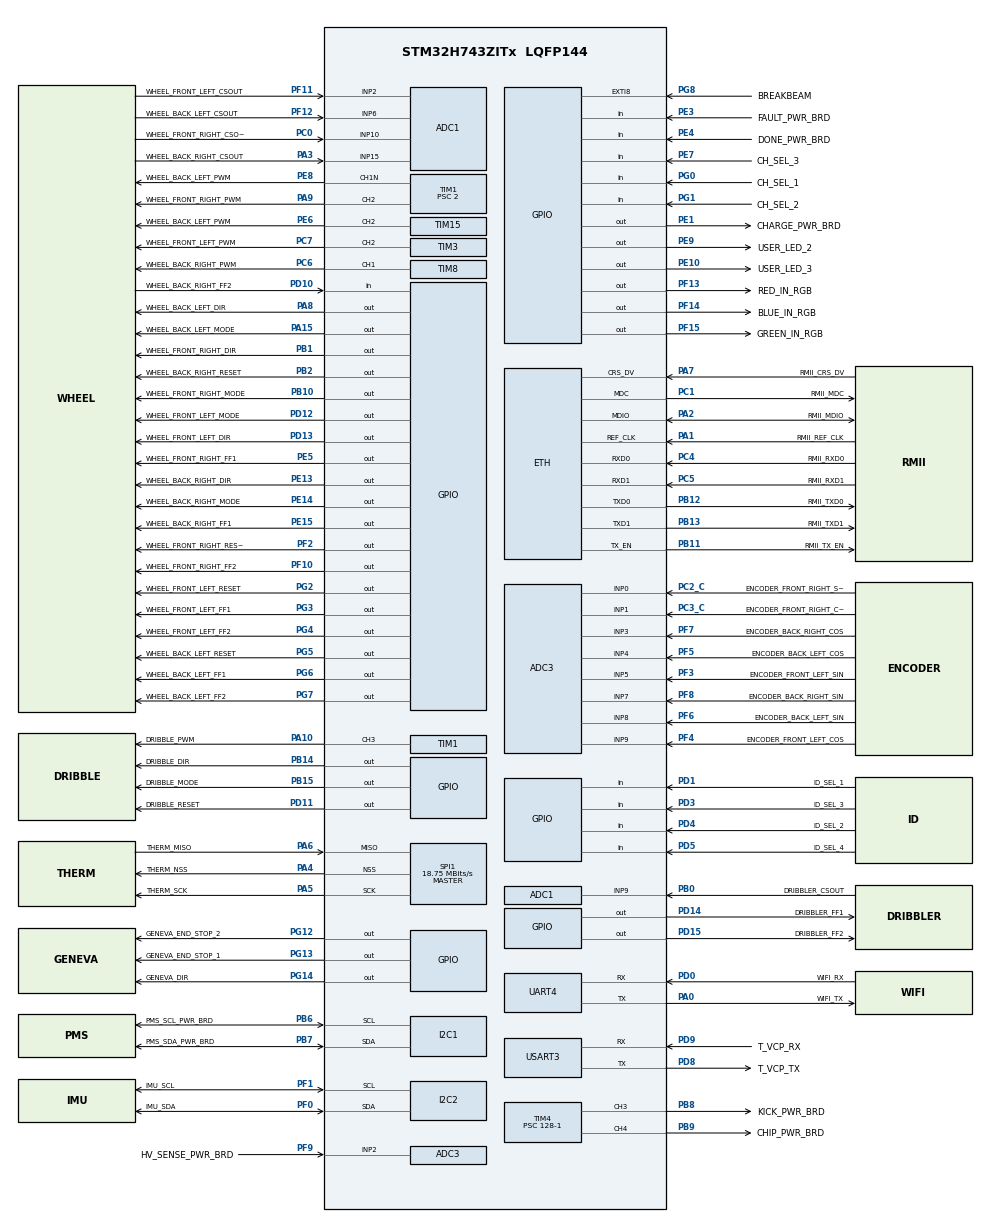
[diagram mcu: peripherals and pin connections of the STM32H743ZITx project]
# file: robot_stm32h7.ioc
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ADC1.Channel-1\#ChannelRegularConversion=ADC_CHANNEL_2
ADC1.ClockPrescaler=ADC_CLOCK_ASYNC_DIV6
ADC1.NbrOfConversionFlag=1
ADC1.OffsetNumber-1\#ChannelRegularConversion=ADC_OFFSET_NONE
ADC1.Rank-1\#ChannelRegularConversion=1
ADC1.SamplingTime-1\#ChannelRegularConversion=ADC_SAMPLETIME_1CYCLE_5
ADC1.master=1
ADC2.Channel-0\#ChannelRegularConversion=ADC_CHANNEL_10
ADC2.ClockPrescaler=ADC_CLOCK_ASYNC_DIV6
ADC2.NbrOfConversionFlag=1
ADC2.OffsetNumber-0\#ChannelRegularConversion=ADC_OFFSET_NONE
ADC2.Rank-0\#ChannelRegularConversion=1
ADC2.SamplingTime-0\#ChannelRegularConversion=ADC_SAMPLETIME_1CYCLE_5
ADC3.Channel-3\#ChannelRegularConversion=ADC_CHANNEL_1
ADC3.ClockPrescaler=ADC_CLOCK_ASYNC_DIV6
ADC3.NbrOfConversionFlag=1
ADC3.OffsetNumber-3\#ChannelRegularConversion=ADC_OFFSET_NONE
ADC3.Rank-3\#ChannelRegularConversion=1
ADC3.SamplingTime-3\#ChannelRegularConversion=ADC_SAMPLETIME_1CYCLE_5
CORTEX_M7.AccessPermission-Cortex_Memory_Protection_Unit_Region0_Settings=MPU_REGION_FULL_ACCESS
CORTEX_M7.AccessPermission-Cortex_Memory_Protection_Unit_Region1_Settings=MPU_REGION_FULL_ACCESS
CORTEX_M7.BaseAddress-Cortex_Memory_Protection_Unit_Region0_Settings=0x30000000
CORTEX_M7.BaseAddress-Cortex_Memory_Protection_Unit_Region1_Settings=0x30024000
CORTEX_M7.CPU_DCache=Enabled
CORTEX_M7.CPU_ICache=Enabled
CORTEX_M7.DisableExec-Cortex_Memory_Protection_Unit_Region0_Settings=MPU_INSTRUCTION_ACCESS_DISABLE
CORTEX_M7.DisableExec-Cortex_Memory_Protection_Unit_Region1_Settings=MPU_INSTRUCTION_ACCESS_DISABLE
CORTEX_M7.Enable-Cortex_Memory_Protection_Unit_Region0_Settings=MPU_REGION_ENABLE
CORTEX_M7.Enable-Cortex_Memory_Protection_Unit_Region1_Settings=MPU_REGION_ENABLE
CORTEX_M7.Enable-Cortex_Memory_Protection_Unit_Region2_Settings=__NULL
CORTEX_M7.IsBufferable-Cortex_Memory_Protection_Unit_Region0_Settings=MPU_ACCESS_NOT_BUFFERABLE
CORTEX_M7.IsBufferable-Cortex_Memory_Protection_Unit_Region1_Settings=MPU_ACCESS_BUFFERABLE
CORTEX_M7.IsCacheable-Cortex_Memory_Protection_Unit_Region1_Settings=MPU_ACCESS_NOT_CACHEABLE
CORTEX_M7.IsShareable-Cortex_Memory_Protection_Unit_Region1_Settings=MPU_ACCESS_NOT_SHAREABLE
CORTEX_M7.MPU_Control=MPU_PRIVILEGED_DEFAULT
CORTEX_M7.Size-Cortex_Memory_Protection_Unit_Region0_Settings=MPU_REGION_SIZE_128KB
CORTEX_M7.Size-Cortex_Memory_Protection_Unit_Region1_Settings=MPU_REGION_SIZE_1KB
CORTEX_M7.TypeExtField-Cortex_Memory_Protection_Unit_Region0_Settings=MPU_TEX_LEVEL1
CORTEX_M7.TypeExtField-Cortex_Memory_Protection_Unit_Region1_Settings=MPU_TEX_LEVEL0
Dma.Request0=UART4_RX
Dma.UART4_RX.0.Direction=DMA_PERIPH_TO_MEMORY
Dma.UART4_RX.0.EventEnable=DISABLE
Dma.UART4_RX.0.FIFOMode=DMA_FIFOMODE_DISABLE
Dma.UART4_RX.0.Instance=DMA1_Stream0
Dma.UART4_RX.0.MemDataAlignment=DMA_MDATAALIGN_BYTE
Dma.UART4_RX.0.MemInc=DMA_MINC_ENABLE
Dma.UART4_RX.0.Mode=DMA_CIRCULAR
Dma.UART4_RX.0.PeriphDataAlignment=DMA_PDATAALIGN_BYTE
Dma.UART4_RX.0.PeriphInc=DMA_PINC_DISABLE
Dma.UART4_RX.0.Polarity=HAL_DMAMUX_REQ_GEN_RISING
Dma.UART4_RX.0.Priority=DMA_PRIORITY_LOW
Dma.UART4_RX.0.RequestNumber=1
Dma.UART4_RX.0.SignalID=NONE
Dma.UART4_RX.0.SyncEnable=DISABLE
Dma.UART4_RX.0.SyncPolarity=HAL_DMAMUX_SYNC_NO_EVENT
Dma.UART4_RX.0.SyncRequestNumber=1
Dma.UART4_RX.0.SyncSignalID=NONE
ETH.ETH_RX_DESC_CNT=0
ETH.ETH_TX_DESC_CNT=0
ETH.MediaInterface=HAL_ETH_RMII_MODE
ETH.RxBuffAddress=0x30040400
ETH.RxBuffLen=1024
ETH.TxDescAddress=0x30040180
FREERTOS.Queues01=RobotLogProtoQ,16,TbotsProto_RobotLog,0,Dynamic,NULL,NULL
FREERTOS.Tasks01=NetStartTask,24,1024,io_proto_multicast_startNetworkingTask,As weak,NULL,Static,NetStartTaskBuffer,NetStartTaskControlBlock;VisionMsgTask,24,1024,io_proto_multicast_listenerTask,As external,(void *)vision_msg_listener_profile,Static,VisionMsgTaskBuffer,VisionMsgTaskControlBlock;PrimMsgTask,24,1024,io_proto_multicast_listenerTask,As external,(void *)primitive_msg_listener_profile,Static,PrimMsgTaskBuffer,PrimMsgTaskControlBlock;RobotStatus,24,1024,io_robot_status_task,As external,(void*)robot_status_msg_sender_profile,Static,RobotStatusBuffer,RobotStatusControlBlock;RobotLogMsgSend,24,1024,io_proto_multicast_senderTask,As external,(void *)robot_log_msg_sender_profile,Static,RobotLogMsgSendBuffer,RobotLogMsgSendControlBlock;NetworkRobotLog,24,1024,io_network_logger_task,As external,(void*)robot_log_msg_sender_profile,Static,NetworkRobotLogBuffer,NetworkRobotLogControlBlock;RobotStatusSend,24,1024,io_proto_multicast_senderTask,As external,(void*)robot_status_msg_sender_profile,Static,RobotStatusSendBuffer,RobotStatusSendControlBlock;PrimExectuor,25,1024,io_primitive_executor_task,As external,NULL,Static,PrimExectuorBuffer,PrimExectuorControlBlock;PrimStarter,24,1024,io_primitive_starter_task,As external,(void *)primitive_msg_listener_profile,Static,PrimStarterBuffer,PrimStarterControlBlock
FREERTOS.configMINIMAL_STACK_SIZE=1024
FREERTOS.configTOTAL_HEAP_SIZE=80720
I2C1.Timeout=0x00008493
I2C1.Timing=0x109093DC
I2C2.Timing=0x109093DC
LWIP.BSP.number=1
LWIP.LWIP_DHCP=0
LWIP.LWIP_IGMP=1
LWIP.LWIP_IPV4=0
LWIP.LWIP_IPV6=1
LWIP.LWIP_MPU_COMPATIBLE=1
LWIP.LWIP_RAM_HEAP_POINTER=0x30020000
LWIP.LWIP_TCP=0
LWIP.LWIP_TCPIP_CORE_LOCKING=1
LWIP.LWIP_TCPIP_CORE_LOCKING_INPUT=1
LWIP.MEMP_MEM_INIT=1
LWIP.MEMP_MEM_MALLOC=0
LWIP.MEM_LIBC_MALLOC=1
LWIP.MEM_SIZE=16000
LWIP.Version=v2.1.2_Cube
LWIP0.BSP.STBoard=false
LWIP0.BSP.api=BSP_COMPONENT_DRIVER
LWIP0.BSP.component=LAN8742
LWIP0.BSP.i2caddr=0
LWIP0.BSP.instance=LAN8742
LWIP0.BSP.name=Driver_PHY
LWIP0.BSP.solution=LAN8742
Mcu.Family=STM32H7
Mcu.Name=STM32H743ZITx
Mcu.Package=LQFP144
NVIC.DMA1_Stream0_IRQn=true\:5\:0\:false\:false\:true\:true\:false\:true
NVIC.ETH_IRQn=true\:5\:0\:false\:false\:true\:true\:true\:true
NVIC.ETH_WKUP_IRQn=true\:5\:0\:false\:false\:true\:true\:true\:true
NVIC.EXTI9_5_IRQn=true\:5\:0\:false\:false\:true\:true\:true\:true
NVIC.PriorityGroup=NVIC_PRIORITYGROUP_4
NVIC.UART4_IRQn=true\:5\:0\:false\:false\:true\:true\:true\:true
NVIC.USART3_IRQn=true\:5\:0\:false\:false\:true\:true\:true\:true
PA0.GPIO_Label=WIFI_TX
PA0.Mode=Asynchronous
PA0.Signal=UART4_TX
PA1.GPIO_Label=RMII_REF_CLK
PA1.Mode=RMII
PA1.Signal=ETH_REF_CLK
PA10.GPIO_Label=DRIBBLE_PWM
PA10.Signal=S_TIM1_CH3
PA11.Signal=S_TIM1_CH4
PA12.Signal=HRTIM_CHD2
PA13\ (JTMS/SWDIO).GPIO_Label=T_SWDIO
PA13\ (JTMS/SWDIO).Mode=Trace_Asynchronous_SW
PA13\ (JTMS/SWDIO).Signal=DEBUG_JTMS-SWDIO
PA14\ (JTCK/SWCLK).GPIO_Label=T_SWCLK
PA14\ (JTCK/SWCLK).Mode=Trace_Asynchronous_SW
PA14\ (JTCK/SWCLK).Signal=DEBUG_JTCK-SWCLK
PA15\ (JTDI).GPIO_Label=WHEEL_BACK_LEFT_MODE
PA15\ (JTDI).Signal=GPIO_Output
PA2.GPIO_Label=RMII_MDIO
PA2.Mode=RMII
PA2.Signal=ETH_MDIO
PA3.GPIO_Label=WHEEL_BACK_RIGHT_CSOUT
PA3.Signal=ADCx_INP15
PA4.GPIO_Label=THERM_NSS
PA4.Mode=NSS_Signal_Hard_Output
PA4.Signal=SPI1_NSS
PA5.GPIO_Label=THERM_SCK
PA5.Mode=RX_Only_Simplex_Unidirect_Master
PA5.Signal=SPI1_SCK
PA6.GPIO_Label=THERM_MISO
PA6.Mode=RX_Only_Simplex_Unidirect_Master
PA6.Signal=SPI1_MISO
PA7.GPIO_Label=RMII_CRS_DV
PA7.Mode=RMII
PA7.Signal=ETH_CRS_DV
PA8.GPIO_Label=WHEEL_BACK_LEFT_DIR
PA8.Signal=GPIO_Output
PA9.GPIO_Label=WHEEL_FRONT_RIGHT_PWM
PA9.Signal=S_TIM1_CH2
PB0.GPIO_Label=DRIBBLER_CSOUT
PB0.Signal=ADCx_INP9
PB1.GPIO_Label=WHEEL_FRONT_RIGHT_DIR
PB1.Signal=GPIO_Output
PB10.GPIO_Label=WHEEL_FRONT_RIGHT_MODE
PB10.Signal=GPIO_Output
PB11.GPIO_Label=RMII_TX_EN
PB11.Mode=RMII
PB11.Signal=ETH_TX_EN
PB12.GPIO_Label=RMII_TXD0
PB12.Mode=RMII
PB12.Signal=ETH_TXD0
PB13.GPIO_Label=RMII_TXD1
PB13.Mode=RMII
PB13.Signal=ETH_TXD1
PB14.GPIO_Label=DRIBBLE_DIR
PB14.Signal=GPIO_Output
PB15.GPIO_Label=DRIBBLE_MODE
PB15.Signal=GPIO_Output
PB2.GPIO_Label=WHEEL_BACK_RIGHT_RESET
PB2.Signal=GPIO_Output
PB3\ (JTDO/TRACESWO).GPIO_Label=T_SWO
PB3\ (JTDO/TRACESWO).Mode=Trace_Asynchronous_SW
PB3\ (JTDO/TRACESWO).Signal=DEBUG_JTDO-SWO
PB5.GPIO_Label=PMS_ALERT_PWR_BRD
PB5.Signal=I2C1_SMBA
PB6.GPIO_Label=PMS_SCL_PWR_BRD
PB6.Mode=I2C
PB6.Signal=I2C1_SCL
PB7.GPIO_Label=PMS_SDA_PWR_BRD
PB7.Mode=I2C
PB7.Signal=I2C1_SDA
PB8.GPIO_Label=KICK_PWR_BRD
PB8.Signal=S_TIM4_CH3
PB9.GPIO_Label=CHIP_PWR_BRD
PB9.Signal=S_TIM4_CH4
PC0.GPIO_Label=WHEEL_FRONT_RIGHT_CSOUT
PC0.Signal=ADCx_INP10
PC1.GPIO_Label=RMII_MDC
PC1.Mode=RMII
PC1.Signal=ETH_MDC
PC10.GPIO_Label=SD_DAT2
PC10.Signal=SDMMC1_D2
PC11.GPIO_Label=SD_DAT3
PC11.Signal=SDMMC1_D3
PC12.GPIO_Label=SD_CLK
PC12.Signal=SDMMC1_CK
PC14-OSC32_IN\ (OSC32_IN).GPIO_Label=PC14-OSC32_IN
PC14-OSC32_IN\ (OSC32_IN).Mode=LSE-External-Oscillator
PC14-OSC32_IN\ (OSC32_IN).Signal=RCC_OSC32_IN
PC15-OSC32_OUT\ (OSC32_OUT).GPIO_Label=PC15-OSC32_OUT
PC15-OSC32_OUT\ (OSC32_OUT).Mode=LSE-External-Oscillator
PC15-OSC32_OUT\ (OSC32_OUT).Signal=RCC_OSC32_OUT
PC2_C.GPIO_Label=ENCODER_FRONT_RIGHT_SIN
PC2_C.Signal=SharedAnalog_PC2
PC3_C.GPIO_Label=ENCODER_FRONT_RIGHT_COS
PC3_C.Mode=IN1-Single-Ended
PC3_C.Signal=ADC3_INP1
PC4.GPIO_Label=RMII_RXD0
PC4.Mode=RMII
PC4.Signal=ETH_RXD0
PC5.GPIO_Label=RMII_RXD1
PC5.Mode=RMII
PC5.Signal=ETH_RXD1
PC6.GPIO_Label=WHEEL_BACK_RIGHT_PWM
PC6.Signal=S_TIM8_CH1
PC7.GPIO_Label=WHEEL_FRONT_LEFT_PWM
PC7.GPIO_PuPd=GPIO_PULLDOWN
PC7.Signal=S_TIM3_CH2
PD0.GPIO_Label=WIFI_RX
PD0.Mode=Asynchronous
PD0.Signal=UART4_RX
PD1.GPIO_Label=ID_SEL_1
PD1.Signal=GPIO_Input
PD10.GPIO_Label=WHEEL_BACK_RIGHT_FF2
PD10.Signal=GPIO_Input
PD11.GPIO_Label=DRIBBLE_RESET
PD11.Signal=GPIO_Output
PD12.GPIO_Label=WHEEL_FRONT_LEFT_MODE
PD12.Signal=GPIO_Output
PD13.GPIO_Label=WHEEL_FRONT_LEFT_DIR
PD13.Signal=GPIO_Output
PD14.GPIO_Label=DRIBBLER_FF1
PD14.Signal=GPIO_Output
PD15.GPIO_Label=DRIBBLER_FF2
PD15.Signal=GPIO_Output
PD2.GPIO_Label=SD_CMD
PD2.Signal=SDMMC1_CMD
PD3.GPIO_Label=ID_SEL_3
PD3.Signal=GPIO_Input
PD4.GPIO_Label=ID_SEL_2
PD4.Signal=GPIO_Input
PD5.GPIO_Label=ID_SEL_4
PD5.Signal=GPIO_Input
PD8.GPIO_Label=T_VCP_TX
PD8.Mode=Asynchronous
PD8.Signal=USART3_TX
PD9.GPIO_Label=T_VCP_RX
PD9.Mode=Asynchronous
PD9.Signal=USART3_RX
PE1.GPIO_Label=CHARGE_PWR_BRD
PE1.Signal=GPIO_Output
PE10.GPIO_Label=USER_LED_3
PE10.Signal=GPIO_Output
PE13.GPIO_Label=WHEEL_BACK_RIGHT_DIR
PE13.Signal=GPIO_Output
PE14.GPIO_Label=WHEEL_BACK_RIGHT_MODE
PE14.Signal=GPIO_Output
PE15.GPIO_Label=WHEEL_BACK_RIGHT_FF1
PE15.Signal=GPIO_Output
PE3.GPIO_Label=FAULT_PWR_BRD
PE3.Signal=GPIO_Input
PE4.GPIO_Label=DONE_PWR_BRD
PE4.Signal=GPIO_Input
PE5.GPIO_Label=WHEEL_FRONT_RIGHT_FF1
PE5.Signal=GPIO_Output
PE6.GPIO_Label=WHEEL_BACK_LEFT_PWM
PE6.Signal=S_TIM15_CH2
PE7.GPIO_Label=CH_SEL_3
PE7.Signal=GPIO_Input
PE8.GPIO_Label=WHEEL_BACK_LEFT_PWM
PE8.Mode=PWM Generation1 CH1N
PE8.Signal=TIM1_CH1N
PE9.GPIO_Label=USER_LED_2
PE9.Signal=GPIO_Output
PF0.GPIO_Label=IMU_SDA
PF0.Mode=I2C
PF0.Signal=I2C2_SDA
PF1.GPIO_Label=IMU_SCL
PF1.Mode=I2C
PF1.Signal=I2C2_SCL
PF10.GPIO_Label=WHEEL_FRONT_RIGHT_FF2
PF10.Signal=GPIO_Output
PF11.GPIO_Label=WHEEL_FRONT_LEFT_CSOUT
PF11.Mode=IN2-Single-Ended
PF11.Signal=ADC1_INP2
PF12.GPIO_Label=WHEEL_BACK_LEFT_CSOUT
PF12.Mode=IN6-Single-Ended
PF12.Signal=ADC1_INP6
PF13.GPIO_Label=RED_IN_RGB
PF13.Signal=GPIO_Output
PF14.GPIO_Label=BLUE_IN_RGB
PF14.Signal=GPIO_Output
PF15.GPIO_Label=GREEN_IN_RGB
PF15.Signal=GPIO_Output
PF2.GPIO_Label=WHEEL_FRONT_RIGHT_RESET
PF2.Signal=GPIO_Output
PF3.GPIO_Label=ENCODER_FRONT_LEFT_SIN
PF3.Mode=IN5-Single-Ended
PF3.Signal=ADC3_INP5
PF4.GPIO_Label=ENCODER_FRONT_LEFT_COS
PF4.Mode=IN9-Single-Ended
PF4.Signal=ADC3_INP9
PF5.GPIO_Label=ENCODER_BACK_LEFT_COS
PF5.Mode=IN4-Single-Ended
PF5.Signal=ADC3_INP4
PF6.GPIO_Label=ENCODER_BACK_LEFT_SIN
PF6.Signal=SharedAnalog_PF6
PF7.GPIO_Label=ENCODER_BACK_RIGHT_COS
PF7.Mode=IN3-Single-Ended
PF7.Signal=ADC3_INP3
PF8.GPIO_Label=ENCODER_BACK_RIGHT_SIN
PF8.Signal=SharedAnalog_PF8
PF9.GPIO_Label=HV_SENSE_PWR_BRD
PF9.Mode=IN2-Single-Ended
PF9.Signal=ADC3_INP2
PG0.GPIO_Label=CH_SEL_1
PG0.Signal=GPIO_Input
PG1.GPIO_Label=CH_SEL_2
PG1.Signal=GPIO_Input
PG12.GPIO_Label=GENEVA_END_STOP_2
PG12.Signal=GPIO_Output
PG13.GPIO_Label=GENEVA_END_STOP_1
PG13.Signal=GPIO_Output
PG14.GPIO_Label=GENEVA_DIR
PG14.Signal=GPIO_Output
PG2.GPIO_Label=WHEEL_FRONT_LEFT_RESET
PG2.Signal=GPIO_Output
PG3.GPIO_Label=WHEEL_FRONT_LEFT_FF1
PG3.Signal=GPIO_Output
PG4.GPIO_Label=WHEEL_FRONT_LEFT_FF2
PG4.Signal=GPIO_Output
PG5.GPIO_Label=WHEEL_BACK_LEFT_RESET
PG5.Signal=GPIO_Output
PG6.GPIO_Label=WHEEL_BACK_LEFT_FF1
PG6.Signal=GPIO_Output
PG7.GPIO_Label=WHEEL_BACK_LEFT_FF2
PG7.Signal=GPIO_Output
PG8.GPIO_Label=BREAKBEAM
PG8.GPIO_ModeDefaultEXTI=GPIO_MODE_IT_FALLING
PG8.GPIO_PuPd=GPIO_PULLUP
PG8.Signal=GPXTI8
PH0-OSC_IN\ (PH0).GPIO_Label=PH0-OSC_IN
PH0-OSC_IN\ (PH0).Mode=HSE-External-Oscillator
PH0-OSC_IN\ (PH0).Signal=RCC_OSC_IN
PH1-OSC_OUT\ (PH1).GPIO_Label=PH1-OSC_OUT
PH1-OSC_OUT\ (PH1).Mode=HSE-External-Oscillator
PH1-OSC_OUT\ (PH1).Signal=RCC_OSC_OUT
ProjectManager.HeapSize=0x200
ProjectManager.StackSize=0x400
ProjectManager.TargetToolchain=Makefile
RCC.48MHZClocksFreq_Value=24000000
RCC.ADCFreq_Value=75000000
RCC.AHBFreq_Value=216000000
RCC.APB1CLKDivider=RCC_HCLK_DIV4
RCC.APB1Freq_Value=75000000
RCC.APB1TimFreq_Value=108000000
RCC.APB2CLKDivider=RCC_HCLK_DIV2
RCC.APB2Freq_Value=75000000
RCC.APB2TimFreq_Value=216000000
RCC.APB3Freq_Value=75000000
RCC.APB4Freq_Value=75000000
RCC.CortexFreq_Value=75000000
RCC.DIVM1=2
RCC.DIVM2=2
RCC.DIVN1=12
RCC.DIVN2=12
RCC.DIVQ1=4
RCC.HCLKFreq_Value=75000000
RCC.HSE_VALUE=25000000
RCC.HSI_VALUE=64000000
RCC.PLL2FRACN=0
RCC.PLLFRACN=0
RCC.PLLM=25
RCC.PLLMUL=RCC_PLL_MUL9
RCC.PLLN=432
RCC.PLLQ=9
RCC.PLLSourceVirtual=RCC_PLLSOURCE_HSE
RCC.PRESCALERUSB=RCC_USBCLKSOURCE_PLL_DIV1_5
RCC.PWR_Regulator_Voltage_Scale=PWR_REGULATOR_VOLTAGE_SCALE1
RCC.SYSCLKFreq_VALUE=75000000
RCC.SYSCLKSource=RCC_SYSCLKSOURCE_PLLCLK
RCC.SYSCLKSourceVirtual=RCC_SYSCLKSOURCE_PLLCLK
RCC.USBFreq_Value=37500000
RCC.VCOOutputFreq_Value=432000000
SH.ADCx_INP10.0=ADC1_INP10,IN10-Single-Ended
SH.ADCx_INP10.1=ADC2_INP10,IN10-Single-Ended
SH.ADCx_INP10.2=ADC3_INP10,IN10-Single-Ended
SH.ADCx_INP15.0=ADC1_INP15,IN15-Single-Ended
SH.ADCx_INP15.1=ADC2_INP15,IN15-Single-Ended
SH.ADCx_INP9.0=ADC1_INP9,IN9-Single-Ended
SH.ADCx_INP9.1=ADC2_INP9,IN9-Single-Ended
SH.S_TIM15_CH2.0=TIM15_CH2,PWM Generation2 CH2
SH.S_TIM1_CH2.0=TIM1_CH2,PWM Generation2 CH2
SH.S_TIM1_CH3.0=TIM1_CH3,PWM Generation3 CH3
SH.S_TIM1_CH4.0=TIM1_CH4
SH.S_TIM3_CH2.0=TIM3_CH2,PWM Generation2 CH2
SH.S_TIM4_CH3.0=TIM4_CH3,PWM Generation3 CH3
SH.S_TIM4_CH4.0=TIM4_CH4,PWM Generation4 CH4
SH.S_TIM8_CH1.0=TIM8_CH1,PWM Generation1 CH1
SH.SharedAnalog_PC2.0=ADC3_INN1
SH.SharedAnalog_PC2.1=ADC3_INP0,IN0-Single-Ended
SH.SharedAnalog_PF6.0=ADC3_INN4
SH.SharedAnalog_PF6.1=ADC3_INP8,IN8-Single-Ended
SH.SharedAnalog_PF8.0=ADC3_INN3
SH.SharedAnalog_PF8.1=ADC3_INP7,IN7-Single-Ended
SPI1.CalculateBaudRate=18.75 MBits/s
SPI1.Direction=SPI_DIRECTION_2LINES_RXONLY
SPI1.Mode=SPI_MODE_MASTER
SPI1.VirtualNSS=VM_NSSHARD
SPI1.VirtualType=VM_MASTER
TIM1.AutoReloadPreload=TIM_AUTORELOAD_PRELOAD_DISABLE
TIM1.Channel-PWM\ Generation1\ CH1N=TIM_CHANNEL_1
TIM1.Channel-PWM\ Generation2\ CH2=TIM_CHANNEL_2
TIM1.Channel-PWM\ Generation3\ CH3=TIM_CHANNEL_3
TIM1.Period=300
TIM1.Prescaler=2
TIM15.Channel-PWM\ Generation2\ CH2=TIM_CHANNEL_2
TIM15.Period=400
TIM15.Prescaler=6
TIM3.AutoReloadPreload=TIM_AUTORELOAD_PRELOAD_DISABLE
TIM3.Channel-PWM\ Generation2\ CH2=TIM_CHANNEL_2
TIM3.Period=400
TIM3.Prescaler=6
TIM4.Channel-PWM\ Generation3\ CH3=TIM_CHANNEL_3
TIM4.Channel-PWM\ Generation4\ CH4=TIM_CHANNEL_4
TIM4.Period=512-1
TIM4.Prescaler=128-1
TIM8.Channel-PWM\ Generation1\ CH1=TIM_CHANNEL_1
TIM8.Period=400
TIM8.Prescaler=6
USART3.VirtualMode-Asynchronous=VM_ASYNC
VP_CRC_VS_CRC.Mode=CRC_Activate
VP_FREERTOS_VS_CMSIS_V2.Mode=CMSIS_V2
VP_LWIP_VS_Enabled.Mode=Enabled
board=NUCLEO-H743ZI

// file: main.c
/* USER CODE BEGIN Header */
/**
 ******************************************************************************
 * @file           : main.c
 * @brief          : Main program body
 ******************************************************************************
 * @attention
 *
 * <h2><center>&copy; Copyright (c) 2020 STMicroelectronics.
 * All rights reserved.</center></h2>
 *
 * This software component is licensed by ST under Ultimate Liberty license
 * SLA0044, the "License"; You may not use this file except in compliance with
 * the License. You may obtain a copy of the License at:
 *                             www.st.com/SLA0044
 *
 ******************************************************************************
 */
#pragma GCC diagnostic push
#pragma GCC diagnostic ignored "-Wsign-conversion"
/* USER CODE END Header */
#include "main.h"

#include "adc.h"
#include "cmsis_os.h"
#include "crc.h"
#include "dma.h"
#include "gpio.h"
#include "i2c.h"
#include "lwip.h"
#include "spi.h"
#include "tim.h"
#include "usart.h"

/* USER CODE BEGIN Includes */
#pragma GCC diagnostic pop

#include "firmware/app/logger/logger.h"
#include "firmware/app/primitives/primitive_manager.h"
#include "firmware/app/world/firmware_robot.h"
#include "firmware/app/world/firmware_world.h"
#include "firmware/boards/robot_stm32h7/io/breakbeam.h"
#include "firmware/boards/robot_stm32h7/io/charger.h"
#include "firmware/boards/robot_stm32h7/io/chicker.h"
#include "firmware/boards/robot_stm32h7/io/dribbler.h"
#include "firmware/boards/robot_stm32h7/io/drivetrain.h"
#include "firmware/boards/robot_stm32h7/io/power_monitor.h"
#include "firmware/boards/robot_stm32h7/io/primitive_executor.h"
#include "firmware/boards/robot_stm32h7/io/uart_logger.h"
#include "firmware/boards/robot_stm32h7/io/vision.h"
#include "firmware/shared/physics.h"

/* USER CODE END Includes */

void SystemClock_Config(void);
void PeriphCommonClock_Config(void);
static void MPU_Config(void);
void MX_FREERTOS_Init(void);

/* USER CODE BEGIN 0 */

// TODO (#2082) remove this hack
float sys_now_float(void);
float sys_now_float(void)
{
    return (float)sys_now();
}

/* USER CODE END 0 */

int main(void)
{

    /* MPU Configuration--------------------------------------------------------*/
    MPU_Config();

    /* Enable I-Cache---------------------------------------------------------*/
    SCB_EnableICache();

    /* Enable D-Cache---------------------------------------------------------*/
    SCB_EnableDCache();

    /* MCU Configuration--------------------------------------------------------*/

    /* Reset of all peripherals, Initializes the Flash interface and the Systick. */
    HAL_Init();

    /* Configure the system clock */
    SystemClock_Config();

    /* Configure the peripherals common clocks */
    PeriphCommonClock_Config();

    /* Initialize all configured peripherals */
    MX_GPIO_Init();
    MX_DMA_Init();
    MX_USART3_UART_Init();
    MX_ADC3_Init();
    MX_I2C1_Init();
    MX_I2C2_Init();
    MX_SPI1_Init();
    MX_ADC1_Init();
    MX_ADC2_Init();
    MX_TIM1_Init();
    MX_TIM3_Init();
    MX_TIM4_Init();
    MX_TIM8_Init();
    MX_UART4_Init();
    MX_CRC_Init();
    MX_TIM15_Init();
    /* USER CODE BEGIN 2 */

    //              ---- Initialize App/IO Layers ----
    //
    // At this point the UART peripheral should be configured correctly
    // so we initialize the UART logger here so that we can see logs
    // from the initialization functions without having to be connected to a network
    io_uart_logger_init(&huart3);
    app_logger_init(0, &io_uart_logger_handleRobotLog);

    TLOG_DEBUG("Initializing I/O Layer");

    initIoDrivetrain();
    initIoNetworking();
    initIoPowerMonitor();
    initIoChicker();

    // Setup the world that acts as the interface for the higher level firmware
    // (like primitives or the controller) to interface with the outside world
    //
    // TODO (#2066) These constants are COMPLETELY WRONG, replace with proper ones
    ForceWheelConstants_t wheel_constants = {
        .wheel_rotations_per_motor_rotation  = GEAR_RATIO,
        .wheel_radius                        = WHEEL_RADIUS,
        .motor_max_voltage_before_wheel_slip = WHEEL_SLIP_VOLTAGE_LIMIT,
        .motor_back_emf_per_rpm              = RPM_TO_VOLT,
        .motor_phase_resistance              = 1,
        .motor_current_per_unit_torque       = CURRENT_PER_TORQUE};

    ForceWheel_t *front_left_wheel = app_force_wheel_create(
        io_drivetrain_applyForceFrontLeftWheel, io_drivetrain_getFrontLeftRpm,
        io_drivetrain_brakeFrontLeft, io_drivetrain_coastFrontLeft, wheel_constants);

    ForceWheel_t *front_right_wheel = app_force_wheel_create(
        io_drivetrain_applyForceFrontRightWheel, io_drivetrain_getFrontRightRpm,
        io_drivetrain_brakeFrontRight, io_drivetrain_coastFrontRight, wheel_constants);

    ForceWheel_t *back_right_wheel = app_force_wheel_create(
        io_drivetrain_applyForceBackRightWheel, io_drivetrain_getBackRightRpm,
        io_drivetrain_brakeBackRight, io_drivetrain_coastBackRight, wheel_constants);

    ForceWheel_t *back_left_wheel = app_force_wheel_create(
        io_drivetrain_applyForceBackLeftWheel, io_drivetrain_getBackLeftRpm,
        io_drivetrain_brakeBackLeft, io_drivetrain_coastBackLeft, wheel_constants);

    Charger_t *charger =
        app_charger_create(io_charger_charge, io_charger_discharge, io_charger_float);

    Chicker_t *chicker =
        app_chicker_create(io_chicker_kick, io_chicker_chip, io_chicker_enable_auto_kick,
                           io_chicker_enable_auto_chip, io_chicker_disable_auto_kick,
                           io_chicker_disable_auto_chip);

    Dribbler_t *dribbler = app_dribbler_create(io_dribbler_setSpeed, io_dribbler_coast,
                                               io_dribbler_getTemperature);

    const RobotConstants_t robot_constants = {
        .mass              = ROBOT_POINT_MASS,
        .moment_of_inertia = INERTIA,
        .robot_radius      = ROBOT_RADIUS,
        .jerk_limit        = JERK_LIMIT,
    };

    ControllerState_t controller_state = {
        .last_applied_acceleration_x       = 0,
        .last_applied_acceleration_y       = 0,
        .last_applied_acceleration_angular = 0,
    };

    FirmwareRobot_t *robot = app_firmware_robot_force_wheels_create(
        charger, chicker, dribbler, io_vision_getRobotPositionX,
        io_vision_getRobotPositionY, io_vision_getRobotOrientation,
        io_vision_getRobotVelocityX, io_vision_getRobotVelocityY,
        io_vision_getRobotAngularVelocity, io_power_monitor_getBatteryVoltage,
        front_right_wheel, front_left_wheel, back_right_wheel, back_left_wheel,
        &controller_state, robot_constants);

    FirmwareBall_t *ball =
        app_firmware_ball_create(io_vision_getBallPositionX, io_vision_getBallPositionY,
                                 io_vision_getBallVelocityX, io_vision_getBallVelocityY);

    FirmwareWorld_t *world = app_firmware_world_create(robot, ball, sys_now_float);

    PrimitiveManager_t *primitive_manager = app_primitive_manager_create();

    io_primitive_executor_init(world, primitive_manager);

    /* USER CODE END 2 */

    /* Init scheduler */
    osKernelInitialize(); /* Call init function for freertos objects (in freertos.c) */
    MX_FREERTOS_Init();
    /* Start scheduler */
    osKernelStart();

    /* We should never get here as control is now taken by the scheduler */
    /* Infinite loop */
    while (1)
    {

    }
}

void SystemClock_Config(void)
{
    RCC_OscInitTypeDef RCC_OscInitStruct = {0};
    RCC_ClkInitTypeDef RCC_ClkInitStruct = {0};

    /** Supply configuration update enable
     */
    HAL_PWREx_ConfigSupply(PWR_LDO_SUPPLY);
    /** Configure the main internal regulator output voltage
     */
    __HAL_PWR_VOLTAGESCALING_CONFIG(PWR_REGULATOR_VOLTAGE_SCALE1);

    while (!__HAL_PWR_GET_FLAG(PWR_FLAG_VOSRDY))
    {
    }
    /** Macro to configure the PLL clock source
     */
    __HAL_RCC_PLL_PLLSOURCE_CONFIG(RCC_PLLSOURCE_HSE);
    /** Initializes the RCC Oscillators according to the specified parameters
     * in the RCC_OscInitTypeDef structure.
     */
    RCC_OscInitStruct.OscillatorType = RCC_OSCILLATORTYPE_HSE;
    RCC_OscInitStruct.HSEState       = RCC_HSE_ON;
    RCC_OscInitStruct.PLL.PLLState   = RCC_PLL_ON;
    RCC_OscInitStruct.PLL.PLLSource  = RCC_PLLSOURCE_HSE;
    RCC_OscInitStruct.PLL.PLLM       = 2;
    RCC_OscInitStruct.PLL.PLLN       = 12;
    RCC_OscInitStruct.PLL.PLLP       = 2;
    RCC_OscInitStruct.PLL.PLLQ       = 4;
    RCC_OscInitStruct.PLL.PLLR       = 2;
    RCC_OscInitStruct.PLL.PLLRGE     = RCC_PLL1VCIRANGE_3;
    RCC_OscInitStruct.PLL.PLLVCOSEL  = RCC_PLL1VCOMEDIUM;
    RCC_OscInitStruct.PLL.PLLFRACN   = 0;
    if (HAL_RCC_OscConfig(&RCC_OscInitStruct) != HAL_OK)
    {
        Error_Handler();
    }
    /** Initializes the CPU, AHB and APB buses clocks
     */
    RCC_ClkInitStruct.ClockType = RCC_CLOCKTYPE_HCLK | RCC_CLOCKTYPE_SYSCLK |
                                  RCC_CLOCKTYPE_PCLK1 | RCC_CLOCKTYPE_PCLK2 |
                                  RCC_CLOCKTYPE_D3PCLK1 | RCC_CLOCKTYPE_D1PCLK1;
    RCC_ClkInitStruct.SYSCLKSource   = RCC_SYSCLKSOURCE_PLLCLK;
    RCC_ClkInitStruct.SYSCLKDivider  = RCC_SYSCLK_DIV1;
    RCC_ClkInitStruct.AHBCLKDivider  = RCC_HCLK_DIV1;
    RCC_ClkInitStruct.APB3CLKDivider = RCC_APB3_DIV1;
    RCC_ClkInitStruct.APB1CLKDivider = RCC_APB1_DIV1;
    RCC_ClkInitStruct.APB2CLKDivider = RCC_APB2_DIV1;
    RCC_ClkInitStruct.APB4CLKDivider = RCC_APB4_DIV1;

    if (HAL_RCC_ClockConfig(&RCC_ClkInitStruct, FLASH_LATENCY_1) != HAL_OK)
    {
        Error_Handler();
    }
}

void PeriphCommonClock_Config(void)
{
    RCC_PeriphCLKInitTypeDef PeriphClkInitStruct = {0};

    /** Initializes the peripherals clock
     */
    PeriphClkInitStruct.PeriphClockSelection = RCC_PERIPHCLK_ADC;
    PeriphClkInitStruct.PLL2.PLL2M           = 2;
    PeriphClkInitStruct.PLL2.PLL2N           = 12;
    PeriphClkInitStruct.PLL2.PLL2P           = 2;
    PeriphClkInitStruct.PLL2.PLL2Q           = 2;
    PeriphClkInitStruct.PLL2.PLL2R           = 2;
    PeriphClkInitStruct.PLL2.PLL2RGE         = RCC_PLL2VCIRANGE_3;
    PeriphClkInitStruct.PLL2.PLL2VCOSEL      = RCC_PLL2VCOMEDIUM;
    PeriphClkInitStruct.PLL2.PLL2FRACN       = 0;
    PeriphClkInitStruct.AdcClockSelection    = RCC_ADCCLKSOURCE_PLL2;
    if (HAL_RCCEx_PeriphCLKConfig(&PeriphClkInitStruct) != HAL_OK)
    {
        Error_Handler();
    }
}

/* MPU Configuration */

void MPU_Config(void)
{
    MPU_Region_InitTypeDef MPU_InitStruct = {0};

    /* Disables the MPU */
    HAL_MPU_Disable();
    /** Initializes and configures the Region and the memory to be protected
     */
    MPU_InitStruct.Enable           = MPU_REGION_ENABLE;
    MPU_InitStruct.Number           = MPU_REGION_NUMBER0;
    MPU_InitStruct.BaseAddress      = 0x30000000;
    MPU_InitStruct.Size             = MPU_REGION_SIZE_128KB;
    MPU_InitStruct.SubRegionDisable = 0x0;
    MPU_InitStruct.TypeExtField     = MPU_TEX_LEVEL1;
    MPU_InitStruct.AccessPermission = MPU_REGION_FULL_ACCESS;
    MPU_InitStruct.DisableExec      = MPU_INSTRUCTION_ACCESS_DISABLE;
    MPU_InitStruct.IsShareable      = MPU_ACCESS_NOT_SHAREABLE;
    MPU_InitStruct.IsCacheable      = MPU_ACCESS_NOT_CACHEABLE;
    MPU_InitStruct.IsBufferable     = MPU_ACCESS_NOT_BUFFERABLE;

    HAL_MPU_ConfigRegion(&MPU_InitStruct);
    /** Initializes and configures the Region and the memory to be protected
     */
    MPU_InitStruct.Number       = MPU_REGION_NUMBER1;
    MPU_InitStruct.BaseAddress  = 0x30024000;
    MPU_InitStruct.Size         = MPU_REGION_SIZE_1KB;
    MPU_InitStruct.TypeExtField = MPU_TEX_LEVEL0;
    MPU_InitStruct.IsBufferable = MPU_ACCESS_BUFFERABLE;

    HAL_MPU_ConfigRegion(&MPU_InitStruct);
    /* Enables the MPU */
    HAL_MPU_Enable(MPU_PRIVILEGED_DEFAULT);
}

void Error_Handler(void)
{
}

/************************ (C) COPYRIGHT STMicroelectronics *****END OF FILE****/

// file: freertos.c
/* USER CODE BEGIN Header */
/**
 ******************************************************************************
 * File Name          : freertos.c
 * Description        : Code for freertos applications
 ******************************************************************************
 * @attention
 *
 * <h2><center>&copy; Copyright (c) 2020 STMicroelectronics.
 * All rights reserved.</center></h2>
 *
 * This software component is licensed by ST under Ultimate Liberty license
 * SLA0044, the "License"; You may not use this file except in compliance with
 * the License. You may obtain a copy of the License at:
 *                             www.st.com/SLA0044
 *
 ******************************************************************************
 */
#pragma GCC diagnostic push
#pragma GCC diagnostic ignored "-Wsign-conversion"
/* USER CODE END Header */

#include "FreeRTOS.h"

#include "cmsis_os.h"
#include "main.h"
#include "task.h"

/* USER CODE BEGIN Includes */
#pragma GCC diagnostic pop
#include "firmware/app/logger/logger.h"
#include "firmware/app/primitives/primitive_manager.h"
#include "firmware/app/world/firmware_robot.h"
#include "firmware/app/world/firmware_world.h"
#include "firmware/boards/robot_stm32h7/io/breakbeam.h"
#include "firmware/boards/robot_stm32h7/io/charger.h"
#include "firmware/boards/robot_stm32h7/io/chicker.h"
#include "firmware/boards/robot_stm32h7/io/dribbler.h"
#include "firmware/boards/robot_stm32h7/io/drivetrain.h"
#include "firmware/boards/robot_stm32h7/io/network_logger.h"
#include "firmware/boards/robot_stm32h7/io/power_monitor.h"
#include "firmware/boards/robot_stm32h7/io/primitive_executor.h"
#include "firmware/boards/robot_stm32h7/io/proto_multicast.h"
#include "firmware/boards/robot_stm32h7/io/proto_multicast_communication_profile.h"
#include "firmware/boards/robot_stm32h7/io/robot_status.h"
#include "firmware/boards/robot_stm32h7/io/uart_logger.h"
#include "firmware/boards/robot_stm32h7/io/ublox_odinw262_communicator.h"
#include "firmware/boards/robot_stm32h7/io/vision.h"
#include "firmware/boards/robot_stm32h7/tim.h"
#include "firmware/boards/robot_stm32h7/usart.h"
#include "firmware/shared/physics.h"
#include "shared/constants.h"
#include "shared/proto/robot_log_msg.nanopb.h"
#include "shared/proto/robot_status_msg.nanopb.h"
#include "shared/proto/tbots_software_msgs.nanopb.h"
/* USER CODE END Includes */

typedef StaticTask_t osStaticThreadDef_t;

/* USER CODE BEGIN Variables */

ProtoMulticastCommunicationProfile_t *robot_status_msg_sender_profile;
ProtoMulticastCommunicationProfile_t *robot_log_msg_sender_profile;
ProtoMulticastCommunicationProfile_t *vision_msg_listener_profile;
ProtoMulticastCommunicationProfile_t *primitive_msg_listener_profile;

static TbotsProto_Vision vision_msg;
static TbotsProto_RobotStatus robot_status_msg;
static TbotsProto_RobotLog robot_log_msg;
static TbotsProto_PrimitiveSet primitive_set_msg;

/* USER CODE END Variables */
/* Definitions for NetStartTask */
osThreadId_t NetStartTaskHandle;
uint32_t NetStartTaskBuffer[1024];
osStaticThreadDef_t NetStartTaskControlBlock;
const osThreadAttr_t NetStartTask_attributes = {
    .name       = "NetStartTask",
    .cb_mem     = &NetStartTaskControlBlock,
    .cb_size    = sizeof(NetStartTaskControlBlock),
    .stack_mem  = &NetStartTaskBuffer[0],
    .stack_size = sizeof(NetStartTaskBuffer),
    .priority   = (osPriority_t)osPriorityNormal,
};
/* Definitions for VisionMsgTask */
osThreadId_t VisionMsgTaskHandle;
uint32_t VisionMsgTaskBuffer[1024];
osStaticThreadDef_t VisionMsgTaskControlBlock;
const osThreadAttr_t VisionMsgTask_attributes = {
    .name       = "VisionMsgTask",
    .cb_mem     = &VisionMsgTaskControlBlock,
    .cb_size    = sizeof(VisionMsgTaskControlBlock),
    .stack_mem  = &VisionMsgTaskBuffer[0],
    .stack_size = sizeof(VisionMsgTaskBuffer),
    .priority   = (osPriority_t)osPriorityNormal,
};
/* Definitions for PrimMsgTask */
osThreadId_t PrimMsgTaskHandle;
uint32_t PrimMsgTaskBuffer[1024];
osStaticThreadDef_t PrimMsgTaskControlBlock;
const osThreadAttr_t PrimMsgTask_attributes = {
    .name       = "PrimMsgTask",
    .cb_mem     = &PrimMsgTaskControlBlock,
    .cb_size    = sizeof(PrimMsgTaskControlBlock),
    .stack_mem  = &PrimMsgTaskBuffer[0],
    .stack_size = sizeof(PrimMsgTaskBuffer),
    .priority   = (osPriority_t)osPriorityNormal,
};
/* Definitions for RobotStatus */
osThreadId_t RobotStatusHandle;
uint32_t RobotStatusBuffer[1024];
osStaticThreadDef_t RobotStatusControlBlock;
const osThreadAttr_t RobotStatus_attributes = {
    .name       = "RobotStatus",
    .cb_mem     = &RobotStatusControlBlock,
    .cb_size    = sizeof(RobotStatusControlBlock),
    .stack_mem  = &RobotStatusBuffer[0],
    .stack_size = sizeof(RobotStatusBuffer),
    .priority   = (osPriority_t)osPriorityNormal,
};
/* Definitions for RobotLogMsgSend */
osThreadId_t RobotLogMsgSendHandle;
uint32_t RobotLogMsgSendBuffer[1024];
osStaticThreadDef_t RobotLogMsgSendControlBlock;
const osThreadAttr_t RobotLogMsgSend_attributes = {
    .name       = "RobotLogMsgSend",
    .cb_mem     = &RobotLogMsgSendControlBlock,
    .cb_size    = sizeof(RobotLogMsgSendControlBlock),
    .stack_mem  = &RobotLogMsgSendBuffer[0],
    .stack_size = sizeof(RobotLogMsgSendBuffer),
    .priority   = (osPriority_t)osPriorityNormal,
};
/* Definitions for NetworkRobotLog */
osThreadId_t NetworkRobotLogHandle;
uint32_t NetworkRobotLogBuffer[1024];
osStaticThreadDef_t NetworkRobotLogControlBlock;
const osThreadAttr_t NetworkRobotLog_attributes = {
    .name       = "NetworkRobotLog",
    .cb_mem     = &NetworkRobotLogControlBlock,
    .cb_size    = sizeof(NetworkRobotLogControlBlock),
    .stack_mem  = &NetworkRobotLogBuffer[0],
    .stack_size = sizeof(NetworkRobotLogBuffer),
    .priority   = (osPriority_t)osPriorityNormal,
};
/* Definitions for RobotStatusSend */
osThreadId_t RobotStatusSendHandle;
uint32_t RobotStatusSendBuffer[1024];
osStaticThreadDef_t RobotStatusSendControlBlock;
const osThreadAttr_t RobotStatusSend_attributes = {
    .name       = "RobotStatusSend",
    .cb_mem     = &RobotStatusSendControlBlock,
    .cb_size    = sizeof(RobotStatusSendControlBlock),
    .stack_mem  = &RobotStatusSendBuffer[0],
    .stack_size = sizeof(RobotStatusSendBuffer),
    .priority   = (osPriority_t)osPriorityNormal,
};
/* Definitions for PrimExectuor */
osThreadId_t PrimExectuorHandle;
uint32_t PrimExectuorBuffer[1024];
osStaticThreadDef_t PrimExectuorControlBlock;
const osThreadAttr_t PrimExectuor_attributes = {
    .name       = "PrimExectuor",
    .cb_mem     = &PrimExectuorControlBlock,
    .cb_size    = sizeof(PrimExectuorControlBlock),
    .stack_mem  = &PrimExectuorBuffer[0],
    .stack_size = sizeof(PrimExectuorBuffer),
    .priority   = (osPriority_t)osPriorityNormal1,
};
/* Definitions for PrimStarter */
osThreadId_t PrimStarterHandle;
uint32_t PrimStarterBuffer[1024];
osStaticThreadDef_t PrimStarterControlBlock;
const osThreadAttr_t PrimStarter_attributes = {
    .name       = "PrimStarter",
    .cb_mem     = &PrimStarterControlBlock,
    .cb_size    = sizeof(PrimStarterControlBlock),
    .stack_mem  = &PrimStarterBuffer[0],
    .stack_size = sizeof(PrimStarterBuffer),
    .priority   = (osPriority_t)osPriorityNormal,
};
/* Definitions for RobotLogProtoQ */
osMessageQueueId_t RobotLogProtoQHandle;
const osMessageQueueAttr_t RobotLogProtoQ_attributes = {.name = "RobotLogProtoQ"};

void io_proto_multicast_startNetworkingTask(void *argument);
extern void io_proto_multicast_listenerTask(void *argument);
extern void io_robot_status_task(void *argument);
extern void io_proto_multicast_senderTask(void *argument);
extern void io_network_logger_task(void *argument);
extern void io_primitive_executor_task(void *argument);
extern void io_primitive_starter_task(void *argument);

extern void MX_LWIP_Init(void);
void MX_FREERTOS_Init(void); /* (MISRA C 2004 rule 8.1) */

void MX_FREERTOS_Init(void)
{

    /* Create the queue(s) */
    /* creation of RobotLogProtoQ */
    RobotLogProtoQHandle =
        osMessageQueueNew(16, sizeof(TbotsProto_RobotLog), &RobotLogProtoQ_attributes);

    /* Create the thread(s) */
    /* creation of NetStartTask */
    NetStartTaskHandle = osThreadNew(io_proto_multicast_startNetworkingTask, NULL,
                                     &NetStartTask_attributes);

    /* creation of VisionMsgTask */
    VisionMsgTaskHandle =
        osThreadNew(io_proto_multicast_listenerTask, (void *)vision_msg_listener_profile,
                    &VisionMsgTask_attributes);

    /* creation of PrimMsgTask */
    PrimMsgTaskHandle =
        osThreadNew(io_proto_multicast_listenerTask,
                    (void *)primitive_msg_listener_profile, &PrimMsgTask_attributes);

    /* creation of RobotStatus */
    RobotStatusHandle =
        osThreadNew(io_robot_status_task, (void *)robot_status_msg_sender_profile,
                    &RobotStatus_attributes);

    /* creation of RobotLogMsgSend */
    RobotLogMsgSendHandle =
        osThreadNew(io_proto_multicast_senderTask, (void *)robot_log_msg_sender_profile,
                    &RobotLogMsgSend_attributes);

    /* creation of NetworkRobotLog */
    NetworkRobotLogHandle =
        osThreadNew(io_network_logger_task, (void *)robot_log_msg_sender_profile,
                    &NetworkRobotLog_attributes);

    /* creation of RobotStatusSend */
    RobotStatusSendHandle =
        osThreadNew(io_proto_multicast_senderTask,
                    (void *)robot_status_msg_sender_profile, &RobotStatusSend_attributes);

    /* creation of PrimExectuor */
    PrimExectuorHandle =
        osThreadNew(io_primitive_executor_task, NULL, &PrimExectuor_attributes);

    /* creation of PrimStarter */
    PrimStarterHandle =
        osThreadNew(io_primitive_starter_task, (void *)primitive_msg_listener_profile,
                    &PrimStarter_attributes);

}

__weak void io_proto_multicast_startNetworkingTask(void *argument)
{
    /* init code for LWIP */
    MX_LWIP_Init();
}

/* USER CODE BEGIN Application */
void initIoNetworking(void)
{
    // TODO channel and robot_id need to be hooked up to the dials on the robot, when
    // available https://github.com/UBC-Thunderbots/Software/issues/1517
    unsigned short int channel = 0;

    // Initialize multicast communication
    io_proto_multicast_init(NETWORK_TIMEOUT_MS);

    primitive_msg_listener_profile = io_proto_multicast_communication_profile_create(
        "primitive_msg_listener_profile", MULTICAST_CHANNELS[channel], PRIMITIVE_PORT,
        &primitive_set_msg, TbotsProto_PrimitiveSet_fields, MAXIMUM_TRANSFER_UNIT_BYTES);

    vision_msg_listener_profile = io_proto_multicast_communication_profile_create(
        "vision_msg_listener_profile", MULTICAST_CHANNELS[channel], VISION_PORT,
        &vision_msg, TbotsProto_Vision_fields, MAXIMUM_TRANSFER_UNIT_BYTES);

    robot_status_msg_sender_profile = io_proto_multicast_communication_profile_create(
        "robot_status_msg_sender", MULTICAST_CHANNELS[channel], ROBOT_STATUS_PORT,
        &robot_status_msg, TbotsProto_RobotStatus_fields, MAXIMUM_TRANSFER_UNIT_BYTES);

    robot_log_msg_sender_profile = io_proto_multicast_communication_profile_create(
        "robot_log_msg_sender", MULTICAST_CHANNELS[channel], ROBOT_LOGS_PORT,
        &robot_log_msg, TbotsProto_RobotLog_fields, MAXIMUM_TRANSFER_UNIT_BYTES);

    // TODO (#2064) mainboard rev 2.0 doens't have a reset pin for the u-blox chip
    // so we can't enable the communicator.
    GpioPin_t *ublox_reset_pin =
        io_gpio_pin_create(ID_SEL_4_GPIO_Port, ID_SEL_4_Pin, ACTIVE_LOW);

    // Initialize the ublox communicator
    io_ublox_odinw262_communicator_init(&huart4, ublox_reset_pin, 2);

    // Initialize network logger
    io_network_logger_init(RobotLogProtoQHandle);
}

void initIoDrivetrain(void)
{
    GpioPin_t *back_left_wheel_reset_pin = io_gpio_pin_create(
        WHEEL_BACK_LEFT_RESET_GPIO_Port, WHEEL_BACK_LEFT_RESET_Pin, ACTIVE_HIGH);
    GpioPin_t *back_left_wheel_mode_pin = io_gpio_pin_create(
        WHEEL_BACK_LEFT_MODE_GPIO_Port, WHEEL_BACK_LEFT_MODE_Pin, ACTIVE_HIGH);
    GpioPin_t *back_left_wheel_dir_pin = io_gpio_pin_create(
        WHEEL_BACK_LEFT_DIR_GPIO_Port, WHEEL_BACK_LEFT_DIR_Pin, ACTIVE_HIGH);

    GpioPin_t *front_left_wheel_reset_pin = io_gpio_pin_create(
        WHEEL_FRONT_LEFT_RESET_GPIO_Port, WHEEL_FRONT_LEFT_RESET_Pin, ACTIVE_HIGH);
    GpioPin_t *front_left_wheel_mode_pin = io_gpio_pin_create(
        WHEEL_FRONT_LEFT_MODE_GPIO_Port, WHEEL_FRONT_LEFT_MODE_Pin, ACTIVE_HIGH);
    GpioPin_t *front_left_wheel_dir_pin = io_gpio_pin_create(
        WHEEL_FRONT_LEFT_DIR_GPIO_Port, WHEEL_FRONT_LEFT_DIR_Pin, ACTIVE_HIGH);

    GpioPin_t *dribbler_reset_pin =
        io_gpio_pin_create(DRIBBLE_RESET_GPIO_Port, DRIBBLE_RESET_Pin, ACTIVE_HIGH);
    GpioPin_t *dribbler_mode_pin =
        io_gpio_pin_create(DRIBBLE_MODE_GPIO_Port, DRIBBLE_MODE_Pin, ACTIVE_HIGH);
    GpioPin_t *dribbler_dir_pin =
        io_gpio_pin_create(DRIBBLE_DIR_GPIO_Port, DRIBBLE_DIR_Pin, ACTIVE_HIGH);

    GpioPin_t *back_right_wheel_reset_pin = io_gpio_pin_create(
        WHEEL_BACK_RIGHT_RESET_GPIO_Port, WHEEL_BACK_RIGHT_RESET_Pin, ACTIVE_HIGH);
    GpioPin_t *back_right_wheel_mode_pin = io_gpio_pin_create(
        WHEEL_BACK_RIGHT_MODE_GPIO_Port, WHEEL_BACK_RIGHT_MODE_Pin, ACTIVE_HIGH);
    GpioPin_t *back_right_wheel_dir_pin = io_gpio_pin_create(
        WHEEL_BACK_RIGHT_DIR_GPIO_Port, WHEEL_BACK_RIGHT_DIR_Pin, ACTIVE_HIGH);

    GpioPin_t *front_right_wheel_reset_pin = io_gpio_pin_create(
        WHEEL_FRONT_RIGHT_RESET_GPIO_Port, WHEEL_FRONT_RIGHT_RESET_Pin, ACTIVE_HIGH);
    GpioPin_t *front_right_wheel_mode_pin = io_gpio_pin_create(
        WHEEL_FRONT_RIGHT_MODE_GPIO_Port, WHEEL_FRONT_RIGHT_MODE_Pin, ACTIVE_HIGH);
    GpioPin_t *front_right_wheel_dir_pin = io_gpio_pin_create(
        WHEEL_FRONT_RIGHT_DIR_GPIO_Port, WHEEL_FRONT_RIGHT_DIR_Pin, ACTIVE_HIGH);

    PwmPin_t *back_left_wheel_pwm_pin   = io_pwm_pin_create(&htim15, TIM_CHANNEL_2);
    PwmPin_t *front_left_wheel_pwm_pin  = io_pwm_pin_create(&htim3, TIM_CHANNEL_2);
    PwmPin_t *dribbler_pwm_pin          = io_pwm_pin_create(&htim1, TIM_CHANNEL_3);
    PwmPin_t *back_right_wheel_pwm_pin  = io_pwm_pin_create(&htim8, TIM_CHANNEL_1);
    PwmPin_t *front_right_wheel_pwm_pin = io_pwm_pin_create(&htim1, TIM_CHANNEL_2);

    AllegroA3931MotorDriver_t *back_left_wheel_driver =
        io_allegro_a3931_motor_driver_create(
            back_left_wheel_pwm_pin, back_left_wheel_reset_pin, back_left_wheel_mode_pin,
            back_left_wheel_dir_pin);
    AllegroA3931MotorDriver_t *front_left_wheel_driver =
        io_allegro_a3931_motor_driver_create(
            front_left_wheel_pwm_pin, front_left_wheel_reset_pin,
            front_left_wheel_mode_pin, front_left_wheel_dir_pin);
    AllegroA3931MotorDriver_t *dribbler_driver = io_allegro_a3931_motor_driver_create(
        dribbler_pwm_pin, dribbler_reset_pin, dribbler_mode_pin, dribbler_dir_pin);
    AllegroA3931MotorDriver_t *back_right_wheel_driver =
        io_allegro_a3931_motor_driver_create(
            back_right_wheel_pwm_pin, back_right_wheel_reset_pin,
            back_right_wheel_mode_pin, back_right_wheel_dir_pin);
    AllegroA3931MotorDriver_t *front_right_wheel_driver =
        io_allegro_a3931_motor_driver_create(
            front_right_wheel_pwm_pin, front_right_wheel_reset_pin,
            front_right_wheel_mode_pin, front_right_wheel_dir_pin);

    DrivetrainUnit_t *drivetrain_unit_back_left_wheel =
        io_drivetrain_unit_create(back_left_wheel_driver);
    DrivetrainUnit_t *drivetrain_unit_front_left_wheel =
        io_drivetrain_unit_create(front_left_wheel_driver);
    DrivetrainUnit_t *drivetrain_unit_back_right_wheel =
        io_drivetrain_unit_create(back_right_wheel_driver);
    DrivetrainUnit_t *drivetrain_unit_front_right_wheel =
        io_drivetrain_unit_create(front_right_wheel_driver);

    io_drivetrain_init(drivetrain_unit_front_left_wheel,
                       drivetrain_unit_front_right_wheel, drivetrain_unit_back_left_wheel,
                       drivetrain_unit_back_right_wheel);

    io_allegro_a3931_motor_setPwmPercentage(dribbler_driver, 0.0f);
}

void initIoPowerMonitor(void)
{
    // TODO (#2097) re-enable once the new mainboard and powerboard revs are in
    //
    // io_power_monitor_init(I2C1, INA226_ADDRESS,
    //                       INA226_MODE_CONT_SHUNT_AND_BUS | INA226_VBUS_140uS |
    //                           INA226_VBUS_140uS | INA226_AVG_1024);
}

void initIoChicker(void)
{
    GpioPin_t *breakbeam_pin =
        io_gpio_pin_create(BREAKBEAM_GPIO_Port, BREAKBEAM_Pin, ACTIVE_HIGH);

    Breakbeam_t *breakbeam = io_breakbeam_create(breakbeam_pin);

    io_chicker_init(breakbeam);
}

/* USER CODE END Application */

/************************ (C) COPYRIGHT STMicroelectronics *****END OF FILE****/
